# RTS591x register map
Vendor: Realtek Semiconductor Corp.; Series: RTS591x Series; File version: 1.0
CPU: ARMV8MML r0p0, little endian, MPU, FPU, VTOR, 3 interrupt priority bits, 4 SAU regions
Registers are 32-bit, read-write, reset 0x0 unless marked. A register's access mark holds for its fields unless they carry their own. Offsets are from the block's base; [hi:lo] are bit positions; {n}, {i} and the like mark numbered series; 'fields as' and 'values as' point back to an identical list.

## AES — Lalu AES Engine
Base 0x40003000
0x00 DATAIN{x} (x=3,2,1,0; step 0x4)
0x10 DATAOUT{x} (x=3,2,1,0; step 0x4)
0x20 KEYDEAOUT{x} (x=7,6,5,4,3,2,1,0; step 0x4) — DECRYPTION KEY REGISTER
0x40 KEY{x} (x=7,6,5,4,3,2,1,0; step 0x4)
0x60 IV{x} (x=3,2,1,0; step 0x4)
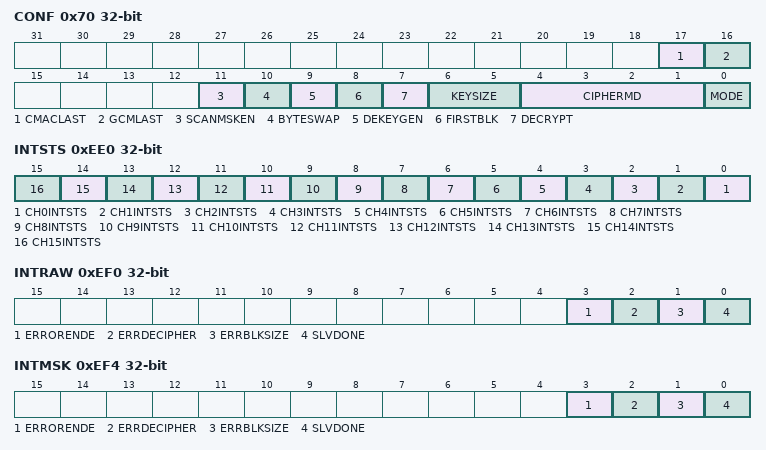
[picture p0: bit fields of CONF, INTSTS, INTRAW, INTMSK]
0x70 CONF — CONFIGURATION REGISTER
  [17] CMACLAST — Indicated The Last Block
  [16] GCMLAST — Indicated The Last Block
  [11] SCANMSKEN — SCA Mask Enable
  [10] BYTESWAP — Byte Swap or Not
  [9] DEKEYGEN — Generate A Key When Decrypting
  [8] FIRSTBLK — First Block
  [7] DECRYPT — Decrypt/Encrypt Selection
    0=DECRYPT (Select decrypt mode); 1=ENCRYPT (Select encrypt mode)
  [6:5] KEYSIZE — Key Size Selection
    0=128_BIT (Select 128-bit); 1=192_BIT (Select 192-bit); 2=256_BIT (Select 256-bit); other=NOT_USED (Reserved values. Do not use.)
  [4:1] CIPHERMD — Cipher Mode Selection
    0=ECB (Select ECB mode); 1=CBC (Select CBC mode); 2=CFB (Select CFB mode); 3=OFB (Select OFB mode); 4=CTR (Select CTR mode); 5=GMAC (Select GMAC mode); 6=GCM (Select GCM mode); 7=CMAC (Select CMAC mode); 8=XTS (Select XTS mode); other=NOT_USED (Reserved values. Do not use.)
  [0] MODE — Engnie Mode Selection
    0=SLV (Select slave mode); 1=DMA (Select dma mode)
0x74 LEN — INPUT LENGTH REGISTER
0x78 GMACLEN{x} (x=1,0; step 0x4) — AAD LENGTH REGISTER
0x80 TAG{x} (x=3,2,1,0; step 0x4)
0x90 GHASHKEY{x} (x=3,2,1,0; step 0x4)
0xEE0 INTSTS — INTERRUPT STATUS REGISTER
  [n] CH{n}INTSTS (n=0..15) — Channel Interrupt Status
0xEF0 INTRAW ro — RAW INTERRUPT STATUS REGISTER
  [3] ERRORENDE — User Uses Operation When Closing
  [2] ERRDECIPHER — User Set a Non-Existent Cipher Mode
  [1] ERRBLKSIZE — Input size is a multiple of 128
  [0] SLVDONE — Slave Mode Completes AES
0xEF4 INTMSK — ENABLE INTERRUPT REGISTER
  [3] ERRORENDE — Enable ERRORENDE Interrupt
  [2] ERRDECIPHER — Enable ERRDECIPHER Interrupt
  [1] ERRBLKSIZE — Enable ERRBLKSIZE Interrupt
  [0] SLVDONE — Enable SLVDONE Interrupt
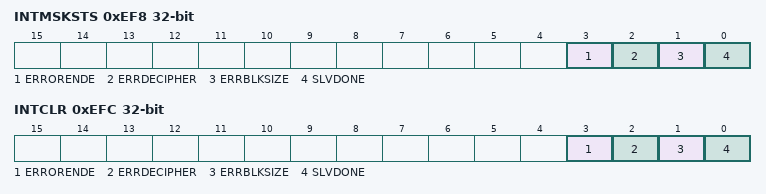
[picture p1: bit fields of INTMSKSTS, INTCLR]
0xEF8 INTMSKSTS — MASKED INTERRUPT STATUS REGISTER
  fields as INTRAW
0xEFC INTCLR — CLEAR INTERRUPT REGISTER
  [3] ERRORENDE — Clear ERRORENDE Interrupt
  [2] ERRDECIPHER — Clear ERRDECIPHER Interrupt
  [1] ERRBLKSIZE — Clear ERRBLKSIZE Interrupt
  [0] SLVDONE — Clear SLVDONE Interrupt

## WDT — WDT Controller
Base 0x4000C000
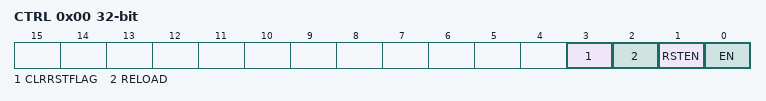
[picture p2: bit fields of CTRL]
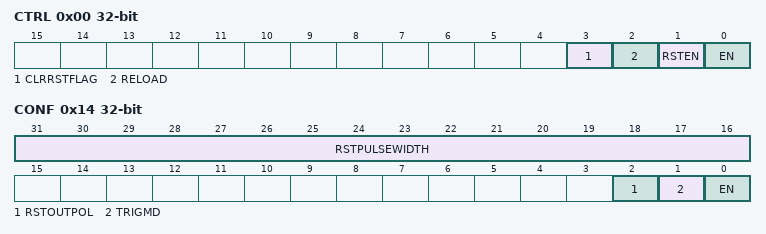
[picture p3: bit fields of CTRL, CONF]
0x00 CTRL — CONTROL REGISTER
  [3] CLRRSTFLAG write-1-clears — Clear WDT reset flag
    0=DO_NOTHING; 1=CLR (Clear WDT reset flag)
  [2] RELOAD — Reload WDT Counter
    0=DO_NOTHING; 1=RELOAD (Reload WDT counter)
  [1] RSTEN — Enable WDT to Reset System
    0=DISABLE (Disable WDT to reset system); 1=ENABLE (Enable WDT to reset system)
  [0] EN — Enable WDT
    0=DISABLE (Disable WDT); 1=ENABLE (Enable WDT)
0x04 STS ro — STATUS REGISTER
  [0] RSTFLAG — Reset Flag
    0=NOT_OCCURRED (WDT reset is not occurred); 1=OCCURRED (WDT reset is occurred)
0x08 CNT — INITIAL COUNTER REGISTER
0x0C DIV — DIVIDER REGISTER
0x10 INTEN — INTERRUPT ENABLE REGISTER
  [0] WDTINTEN — Enable WDT Interrupt
    0=DISBLE (Disable WDT interrupt); 1=ENABLE (Enable WDT interrupt)

## PWRBTN — Power Button Over WDT Controller
Base 0x4000C014
0x00 CTRL — CONTROL REGISTER
  [3] CLRRSTFLAG write-1-clears — Clear WDT reset flag
    0=DO_NOTHING; 1=CLR (Clear WDT reset flag)
  [2] RELOAD — Reload WDT Counter
    0=DO_NOTHING; 1=RELOAD (Reload WDT counter)
  [1] RSTEN — Enable WDT to Reset System
    0=DISABLE (Disable WDT to reset system); 1=ENABLE (Enable WDT to reset system)
  [0] EN — Enable WDT
    0=DISABLE (Disable WDT); 1=ENABLE (Enable WDT)
0x04 STS ro — STATUS REGISTER
  [0] RSTFLAG — Reset Flag
    0=NOT_OCCURRED (WDT reset is not occurred); 1=OCCURRED (WDT reset is occurred)
0x08 CNT — INITIAL COUNTER REGISTER
  [7:0] CNT — Counter value
0x0C DIV — DIVIDER REGISTER
  [15:0] DIV — Divider value
0x10 INTEN — INTERRUPT ENABLE REGISTER
  [0] WDTINTEN — Enable WDT Interrupt
    0=DISBLE (Disable WDT interrupt); 1=ENABLE (Enable WDT interrupt)
0x14 CONF — PWRBTN CONTROL REGISTER
  [31:16] RSTPULSEWIDTH — Reset Output Pulse Width
  [2] RSTOUTPOL — Reset Output Polarity
    0=LOW (Active low); 1=HIGH (Active high)
  [1] TRIGMD — Trigger Level Selection
    0=LOW (Low-level trigger); 1=HIGH (High-level trigger)
  [0] EN — Enable Power Button Function
    0=DISBLE (Disable power button function); 1=ENABLE (Enable power button function)
